# nrf54ls05b_enga_application register map
Vendor: Nordic Semiconductor; Series: nrf54l; File version: 1
CPU: CM33 r0p4, little endian, no MPU, no FPU, 3 interrupt priority bits, 270 interrupts
Registers are 32-bit, read-write, reset 0x0 unless marked. A register's access mark holds for its fields unless they carry their own. Offsets are from the block's base; [hi:lo] are bit positions; lines under a group give offsets from that group; {n}, {i} and the like mark numbered series.

## GLOBAL_EGU00 — Event generator unit 0
Base 0x40058000
Same registers: GLOBAL_EGU10 0x40087000, GLOBAL_EGU20 0x400C9000
{0x0+4i} TASKS_TRIGGER[{i}] (i=0..15) wo — Description collection: Trigger n for triggering the corresponding TRIGGERED[n] event
  [0] TASKS_TRIGGER — Trigger n for triggering the corresponding TRIGGERED[n] event
    1=Trigger task
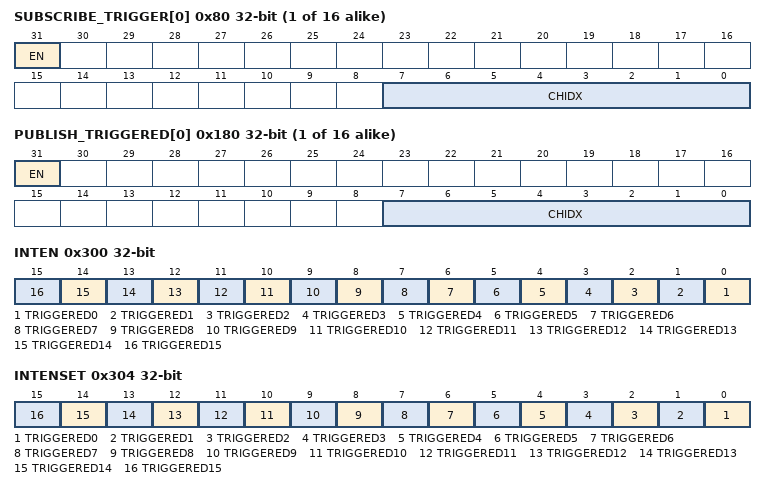
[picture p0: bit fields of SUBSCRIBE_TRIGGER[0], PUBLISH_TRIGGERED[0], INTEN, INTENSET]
{0x80+4i} SUBSCRIBE_TRIGGER[{i}] (i=0..15) — Description collection: Subscribe configuration for task TRIGGER[n]
  [31] EN
    0=Disabled (Disable subscription); 1=Enabled (Enable subscription)
  [7:0] CHIDX — DPPI channel that task TRIGGER[n] will subscribe to
{0x100+4i} EVENTS_TRIGGERED[{i}] (i=0..15) — Description collection: Event number n generated by triggering the corresponding TRIGGER[n] task
  [0] EVENTS_TRIGGERED — Event number n generated by triggering the corresponding TRIGGER[n] task
    0=NotGenerated (Event not generated); 1=Generated (Event generated)
{0x180+4i} PUBLISH_TRIGGERED[{i}] (i=0..15) — Description collection: Publish configuration for event TRIGGERED[n]
  [31] EN
    0=Disabled (Disable publishing); 1=Enabled (Enable publishing)
  [7:0] CHIDX — DPPI channel that event TRIGGERED[n] will publish to
0x300 INTEN — Enable or disable interrupt
  [all] fields
    0=Disabled; 1=Enabled
  [n] TRIGGERED{n} (n=0..15) — Enable or disable interrupt for event TRIGGERED[{n}]
0x304 INTENSET — Enable interrupt
  [all] fields
    on read: 0=Disabled (Read: Disabled); 1=Enabled (Read: Enabled) | on write: 1=Set (Enable)
  [n] TRIGGERED{n} (n=0..15) — Write '1' to enable interrupt for event TRIGGERED[{n}]
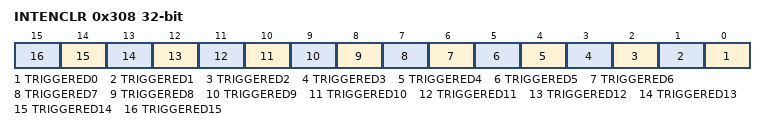
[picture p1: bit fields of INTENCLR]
0x308 INTENCLR — Disable interrupt
  [all] fields
    on read: 0=Disabled (Read: Disabled); 1=Enabled (Read: Enabled) | on write: 1=Clear (Disable)
  [n] TRIGGERED{n} (n=0..15) — Write '1' to disable interrupt for event TRIGGERED[{n}]

## GLOBAL_TRNG — CRACEN TRNG
Base 0x40059000; alternate view of GLOBAL_CRACENCORE
0x104 EVENTS_RNG — Event indicating that interrupt triggered at RNG
  [0] EVENTS_RNG
    0=NotGenerated (Event not generated); 1=Generated (Event generated)
0x300 INTEN — Enable or disable interrupt
  [1] RNG — Enable or disable interrupt for event RNG
    0=Disabled; 1=Enabled
0x304 INTENSET — Enable interrupt
  [1] RNG — Write '1' to enable interrupt for event RNG
    on read: 0=Disabled (Read: Disabled); 1=Enabled (Read: Enabled) | on write: 1=Set (Enable)
0x308 INTENCLR — Disable interrupt
  [1] RNG — Write '1' to disable interrupt for event RNG
    on read: 0=Disabled (Read: Disabled); 1=Enabled (Read: Enabled) | on write: 1=Clear (Disable)
0x30C INTPEND ro — Pending interrupts
  [1] RNG — Read pending status of interrupt for event RNG
    on read: 0=NotPending (Read: Not pending); 1=Pending (Read: Pending)
0x400 ENABLE — Enable RNG peripheral module.
  [1] RNG — Enable RNG
    0=Disabled (RNG disabled.); 1=Enabled (RNG enabled.)
0xC00 PCGCSLAVE group — Unspecified
  {0x0+4j} PENALTY[{j}] (j=0..1) reset 0xFFFFFFFC — Description collection: Penalty level for power/clock pair n. When FULL_PCP_ZERO feature is not supported, PENALTY[0] address overlaps the PENALTY0 address and register description for PENALTY[0] is not valid.
    [1:0] PENALTY — Penalty level
  0x00 PENALTY0 (alternate view of PENALTY[*]) — Penalty level for power/clock pair 0. The register description is valid only when FULL_PCP_ZERO feature is not supported
    [1:0] PENALTY ro — Penalty level

## GLOBAL_PULSEDET00 — PULSEDET peripheral 0
Base 0x4007A000
Same registers: GLOBAL_PULSEDET10 0x400A0000, GLOBAL_PULSEDET20 0x400EC000, GLOBAL_PULSEDET30 0x40110000
0x00 TASKS_RESET wo — Reset PULSEDET analog macros
  [0] TASKS_RESET
    1=Trigger task
0x400 STATUSANA ro — Status register for analog macro cells (32*n) to 32*(n+1)-1. Status registers offsets :0x400+0x4*n, n = 1:64
0x500 ENABLE — Enable tamper event and automatic reset.
  [0] ENABLE
0x504 DETMASK reset 0xFF — Mask detectors in the PULSEDET analog macros
  [7:0] DETMASK
0x508 INSTMASK reset 0xFFFFFFFF — Mask PULSEDET analog macro instances
